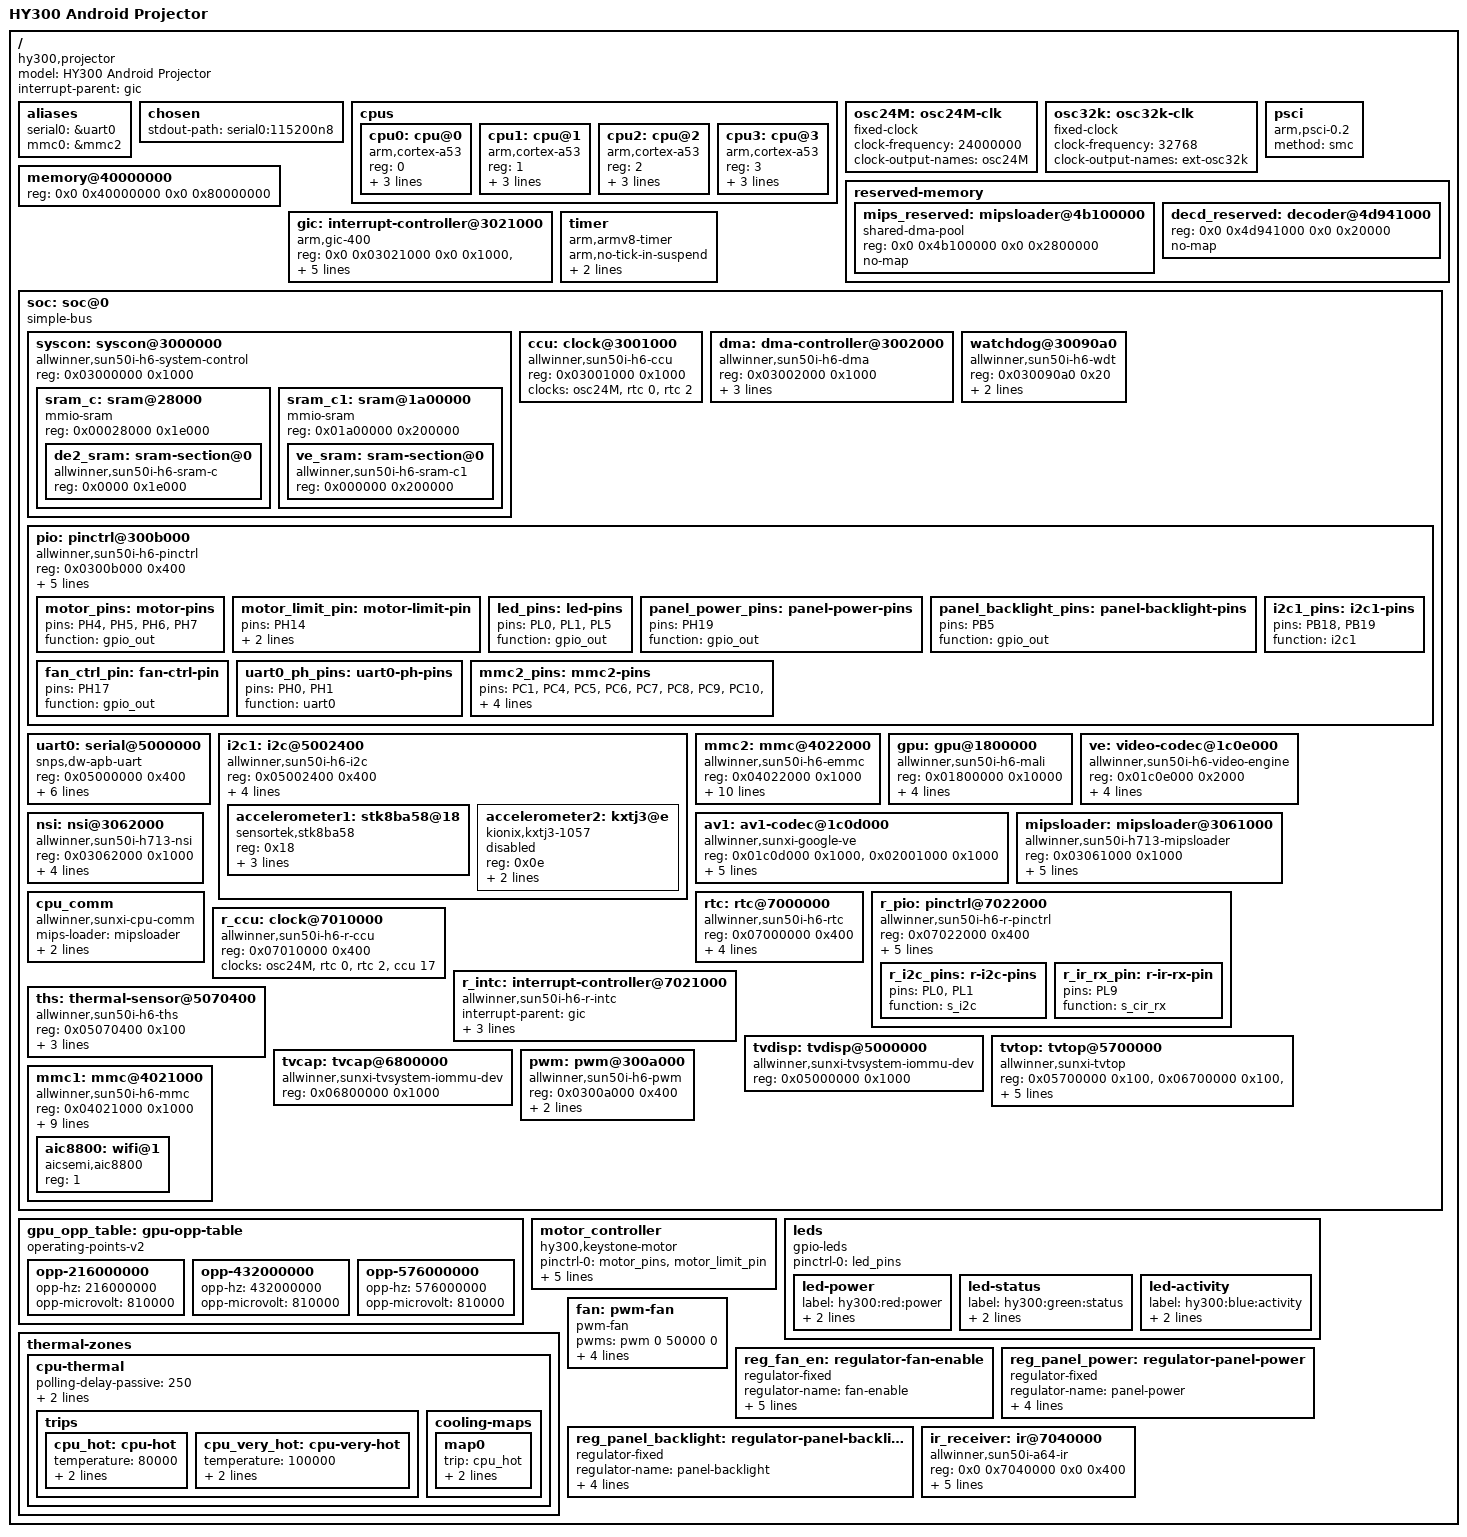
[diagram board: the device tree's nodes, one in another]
// SPDX-License-Identifier: (GPL-2.0+ OR MIT)
/*
 * Device Tree for HY300 Android Projector with Allwinner H713 SoC
 * 
 * Based on hardware analysis from factory DTB files:
 * - Allwinner H713 SoC (sun50iw12p1, tv303 platform)
 * - MIPS co-processor for display subsystem
 * - Mali-Midgard GPU architecture
 * - Projector-specific hardware (motors, sensors, thermal management)
 *
 * Copyright (c) 2025 Linux on HY300 Project
 */

/dts-v1/;

/ {
	model = "HY300 Android Projector";
	compatible = "hy300,projector", "allwinner,sun50i-h713", "allwinner,sun50i-h6";

	#address-cells = <2>;
	#size-cells = <2>;

	interrupt-parent = <&gic>;

	aliases {
		serial0 = &uart0;
		mmc0 = &mmc2;
	};

	chosen {
		stdout-path = "serial0:115200n8";
	};

	/*
	 * ARM Cortex-A53 CPU configuration
	 * H713 SoC: Quad-core ARM64 Cortex-A53
	 */
	cpus {
		#address-cells = <1>;
		#size-cells = <0>;

		cpu0: cpu@0 {
			compatible = "arm,cortex-a53";
			device_type = "cpu";
			reg = <0>;
			enable-method = "psci";
			clocks = <&ccu 0>; /* CLK_CPUX */
			clock-latency-ns = <244144>; /* 8 32k periods */
			#cooling-cells = <2>;
		};

		cpu1: cpu@1 {
			compatible = "arm,cortex-a53";
			device_type = "cpu";
			reg = <1>;
			enable-method = "psci";
			clocks = <&ccu 0>; /* CLK_CPUX */
			clock-latency-ns = <244144>; /* 8 32k periods */
			#cooling-cells = <2>;
		};

		cpu2: cpu@2 {
			compatible = "arm,cortex-a53";
			device_type = "cpu";
			reg = <2>;
			enable-method = "psci";
			clocks = <&ccu 0>; /* CLK_CPUX */
			clock-latency-ns = <244144>; /* 8 32k periods */
			#cooling-cells = <2>;
		};

		cpu3: cpu@3 {
			compatible = "arm,cortex-a53";
			device_type = "cpu";
			reg = <3>;
			enable-method = "psci";
			clocks = <&ccu 0>; /* CLK_CPUX */
			clock-latency-ns = <244144>; /* 8 32k periods */
			#cooling-cells = <2>;
		};
	};

	/*
	 * External oscillators - using H6 reference values
	 * H713 uses same crystal configuration as H6
	 */
	osc24M: osc24M-clk {
		#clock-cells = <0>;
		compatible = "fixed-clock";
		clock-frequency = <24000000>;
		clock-output-names = "osc24M";
	};

	osc32k: osc32k-clk {
		#clock-cells = <0>;
		compatible = "fixed-clock";
		clock-frequency = <32768>;
		clock-output-names = "ext-osc32k";
	};

	/*
	 * Power management and CPU idle
	 */
	psci {
		compatible = "arm,psci-0.2";
		method = "smc";
	};

	/*
	 * Memory configuration
	 * DRAM parameters extracted from boot0.bin:
	 * - DDR3-1600 configuration
	 * - Factory configuration supports up to 4GB
	 */
	memory@40000000 {
		device_type = "memory";
		/* Memory size will be filled by U-Boot */
		reg = <0x0 0x40000000 0x0 0x80000000>; /* 2GB default */
	};

	/*
	 * Reserved memory regions for special hardware
	 * Based on factory DTB analysis: MIPS co-processor and decoders
	 */
	reserved-memory {
		#address-cells = <2>;
		#size-cells = <2>;
		ranges;

		/*
		 * MIPS co-processor firmware and working memory
		 * Exact 40MB allocation based on factory memory layout analysis
		 */
		mips_reserved: mipsloader@4b100000 {
			compatible = "shared-dma-pool";
			reg = <0x0 0x4b100000 0x0 0x2800000>; /* 40MB */
			no-map;
		};

		/*
		 * Video decoder buffer
		 * Factory configuration: 0x4d941000 size 0x20000 (128KB)
		 */
		decd_reserved: decoder@4d941000 {
			reg = <0x0 0x4d941000 0x0 0x20000>;
			no-map;
		};
	};

	/*
	 * ARM Generic Interrupt Controller
	 * H713 uses same GIC configuration as H6
	 */
	gic: interrupt-controller@3021000 {
		compatible = "arm,gic-400";
		reg = <0x0 0x03021000 0x0 0x1000>,
		      <0x0 0x03022000 0x0 0x2000>,
		      <0x0 0x03024000 0x0 0x2000>,
		      <0x0 0x03026000 0x0 0x2000>;
		interrupts = <1 9 0xff04>; /* GIC_PPI 9 (GIC_CPU_MASK_SIMPLE(4) | IRQ_TYPE_LEVEL_HIGH) */
		interrupt-controller;
		#interrupt-cells = <3>;
	};

	/*
	 * Timer configuration
	 * ARM architected timer - H6 compatible
	 */
	timer {
		compatible = "arm,armv8-timer";
		arm,no-tick-in-suspend;
		interrupts = <1 13 0xff08>, /* GIC_PPI 13 (GIC_CPU_MASK_SIMPLE(4) | IRQ_TYPE_LEVEL_LOW) */
			     <1 14 0xff08>, /* GIC_PPI 14 (GIC_CPU_MASK_SIMPLE(4) | IRQ_TYPE_LEVEL_LOW) */
			     <1 11 0xff08>, /* GIC_PPI 11 (GIC_CPU_MASK_SIMPLE(4) | IRQ_TYPE_LEVEL_LOW) */
			     <1 10 0xff08>; /* GIC_PPI 10 (GIC_CPU_MASK_SIMPLE(4) | IRQ_TYPE_LEVEL_LOW) */
	};

	soc: soc@0 {
		compatible = "simple-bus";
		#address-cells = <1>;
		#size-cells = <1>;
		ranges = <0x0 0x0 0x0 0x40000000>;

		/*
		 * System Control Unit
		 * H713 system control - H6 compatible
		 */
		syscon: syscon@3000000 {
			compatible = "allwinner,sun50i-h6-system-control";
			reg = <0x03000000 0x1000>;
			#address-cells = <1>;
			#size-cells = <1>;
			ranges;

			sram_c: sram@28000 {
				compatible = "mmio-sram";
				reg = <0x00028000 0x1e000>;
				#address-cells = <1>;
				#size-cells = <1>;
				ranges = <0 0x00028000 0x1e000>;

				de2_sram: sram-section@0 {
					compatible = "allwinner,sun50i-h6-sram-c",
						     "allwinner,sun50i-a64-sram-c";
					reg = <0x0000 0x1e000>;
				};
			};

			sram_c1: sram@1a00000 {
				compatible = "mmio-sram";
				reg = <0x01a00000 0x200000>;
				#address-cells = <1>;
				#size-cells = <1>;
				ranges = <0 0x01a00000 0x200000>;

				ve_sram: sram-section@0 {
					compatible = "allwinner,sun50i-h6-sram-c1",
						     "allwinner,sun4i-a10-sram-c1";
					reg = <0x000000 0x200000>;
				};
			};
		};

		/*
		 * Clock Control Unit
		 * H713 CCU - H6 compatible with tv303 platform extensions
		 */
		ccu: clock@3001000 {
			compatible = "allwinner,sun50i-h6-ccu";
			reg = <0x03001000 0x1000>;
			clocks = <&osc24M>, <&rtc 0>, <&rtc 2>;
			clock-names = "hosc", "losc", "iosc";
			#clock-cells = <1>;
			#reset-cells = <1>;
		};

		/*
		 * DMA Controller
		 * H6-compatible DMA for peripheral access
		 */
		dma: dma-controller@3002000 {
			compatible = "allwinner,sun50i-h6-dma";
			reg = <0x03002000 0x1000>;
			interrupts = <0 43 4>; /* GIC_SPI 43 IRQ_TYPE_LEVEL_HIGH */
			clocks = <&ccu 1>, <&ccu 2>, <&ccu 125>; /* CLK_BUS_DMA, CLK_MBUS_DMA, CLK_VINCAP_DMA */
			clock-names = "bus", "mbus", "vincap";
			resets = <&ccu 0>; /* RST_BUS_DMA */
			#dma-cells = <1>;
		};

		/*
		 * Watchdog Timer
		 * H6-compatible watchdog
		 */
		watchdog@30090a0 {
			compatible = "allwinner,sun50i-h6-wdt",
				     "allwinner,sun6i-a31-wdt";
			reg = <0x030090a0 0x20>;
			interrupts = <0 50 4>; /* GIC_SPI 50 IRQ_TYPE_LEVEL_HIGH */
			clocks = <&osc24M>;
		};

		/*
		 * Pin Controller
		 * H713 pinctrl with projector-specific GPIO assignments
		 */
		pio: pinctrl@300b000 {
			compatible = "allwinner,sun50i-h6-pinctrl";
			reg = <0x0300b000 0x400>;
			interrupt-parent = <&r_intc>;
			interrupts = <0 51 4>, /* GIC_SPI 51 IRQ_TYPE_LEVEL_HIGH */
				     <0 53 4>, /* GIC_SPI 53 IRQ_TYPE_LEVEL_HIGH */
				     <0 54 4>, /* GIC_SPI 54 IRQ_TYPE_LEVEL_HIGH */
				     <0 59 4>; /* GIC_SPI 59 IRQ_TYPE_LEVEL_HIGH */
			clocks = <&ccu 5>, <&osc24M>, <&rtc 0>; /* CLK_APB1 */
			clock-names = "apb", "hosc", "losc";
			gpio-controller;
			#gpio-cells = <3>;
			interrupt-controller;
			#interrupt-cells = <3>;

			/*
			 * Projector-specific GPIO configurations
			 * Based on factory DTB analysis from HY300_SPECIFIC_HARDWARE.md
			 */

			/* Motor control for electronic keystone correction */
			motor_pins: motor-pins {
				pins = "PH4", "PH5", "PH6", "PH7";
				function = "gpio_out";
			};

			motor_limit_pin: motor-limit-pin {
				pins = "PH14";
				function = "gpio_in";
				bias-pull-up;
			};

			/* Status LEDs */
			led_pins: led-pins {
				pins = "PL0", "PL1", "PL5";
				function = "gpio_out";
			};

			/* Panel power control */
			panel_power_pins: panel-power-pins {
				pins = "PH19";
				function = "gpio_out";
			};

			panel_backlight_pins: panel-backlight-pins {
				pins = "PB5";
				function = "gpio_out";
			};

			/* Fan control */
			fan_ctrl_pin: fan-ctrl-pin {
				pins = "PH17";
				function = "gpio_out";
			};

			/* UART0 for debug console */
			uart0_ph_pins: uart0-ph-pins {
				pins = "PH0", "PH1";
				function = "uart0";
			};

			/* I2C for sensors */
			i2c1_pins: i2c1-pins {
				pins = "PB18", "PB19";
				function = "i2c1";
			};

			/* MMC2 for eMMC */
			mmc2_pins: mmc2-pins {
				pins = "PC1", "PC4", "PC5", "PC6", "PC7",
				       "PC8", "PC9", "PC10", "PC11", "PC12",
				       "PC13", "PC14", "PC15", "PC16";
				function = "mmc2";
				drive-strength = <30>;
				bias-pull-up;
			};
		};

		/*
		 * UART0 - Debug console
		 * Primary debug interface for the system
		 */
		uart0: serial@5000000 {
			compatible = "snps,dw-apb-uart";
			reg = <0x05000000 0x400>;
			interrupts = <0 0 4>; /* GIC_SPI 0 IRQ_TYPE_LEVEL_HIGH */
			reg-shift = <2>;
			reg-io-width = <4>;
			clocks = <&ccu 6>; /* CLK_BUS_UART0 */
			resets = <&ccu 2>; /* RST_BUS_UART0 */
			pinctrl-names = "default";
			pinctrl-0 = <&uart0_ph_pins>;
			status = "okay";
		};

		/*
		 * I2C1 - Sensors
		 * Connected to accelerometers for auto-keystone correction
		 */
		i2c1: i2c@5002400 {
			compatible = "allwinner,sun50i-h6-i2c",
				     "allwinner,sun6i-a31-i2c";
			reg = <0x05002400 0x400>;
			interrupts = <0 7 4>; /* GIC_SPI 7 IRQ_TYPE_LEVEL_HIGH */
			clocks = <&ccu 7>; /* CLK_BUS_I2C1 */
			resets = <&ccu 3>; /* RST_BUS_I2C1 */
			pinctrl-names = "default";
			pinctrl-0 = <&i2c1_pins>;
			status = "okay";
			#address-cells = <1>;
			#size-cells = <0>;

			/*
			 * Accelerometer sensors for keystone correction
			 * Factory DTB shows two different accelerometer models with interrupt GPIOs
			 */
			accelerometer1: stk8ba58@18 {
				compatible = "sensortek,stk8ba58";
				reg = <0x18>;
				interrupt-parent = <&pio>;
				interrupts = <1 0 2>; /* PB0, IRQ_TYPE_EDGE_FALLING */
				stk,direction = <2>;
			};

			/* Alternative accelerometer - different I2C address from factory analysis */
			accelerometer2: kxtj3@e {
				compatible = "kionix,kxtj3-1057";
				reg = <0x0e>; /* Factory DTB uses 0x0e, not 0x18 */
				interrupt-parent = <&pio>;
				interrupts = <1 0 2>; /* PB0, IRQ_TYPE_EDGE_FALLING */
				status = "disabled"; /* Enable based on hardware detection */
			};

			/* Alternative accelerometer - may be different hardware revisions */
		};

		/*
		 * MMC2 - eMMC Storage
		 * Primary storage device
		 */
		mmc2: mmc@4022000 {
			compatible = "allwinner,sun50i-h6-emmc",
				     "allwinner,sun50i-a64-emmc";
			reg = <0x04022000 0x1000>;
			interrupts = <0 37 4>; /* GIC_SPI 37 IRQ_TYPE_LEVEL_HIGH */
			clocks = <&ccu 3>, <&ccu 4>; /* CLK_BUS_MMC2, CLK_MMC2 */
			clock-names = "ahb", "mmc";
			resets = <&ccu 1>; /* RST_BUS_MMC2 */
			reset-names = "ahb";
			pinctrl-names = "default";
			pinctrl-0 = <&mmc2_pins>;
			max-frequency = <150000000>;
			cap-mmc-highspeed;
			mmc-ddr-1_8v;
			mmc-hs200-1_8v;
			non-removable;
			bus-width = <8>;
			status = "okay";
		};

		/*
		 * GPU - Mali-Midgard
		 * Factory DTB shows mali-midgard compatible GPU
		 * Memory base: 0x01800000, register space: 64KB
		 */
		gpu: gpu@1800000 {
			compatible = "allwinner,sun50i-h6-mali",
				     "arm,mali-midgard";
			reg = <0x01800000 0x10000>;
			interrupts = <0 117 4>, /* GIC_SPI 117 IRQ_TYPE_LEVEL_HIGH */
				     <0 118 4>, /* GIC_SPI 118 IRQ_TYPE_LEVEL_HIGH */
				     <0 76 4>;  /* GIC_SPI 76 IRQ_TYPE_LEVEL_HIGH */
			interrupt-names = "job", "mmu", "gpu";
			clocks = <&ccu 8>, <&ccu 9>; /* CLK_GPU, CLK_BUS_GPU */
			clock-names = "core", "bus";
			resets = <&ccu 4>; /* RST_BUS_GPU */
			status = "okay";

			operating-points-v2 = <&gpu_opp_table>;
		};

		/*
		 * Video Engine - CedarX VPU
		 * Hardware video decoding for H.264, H.265, VP8, VP9
		 * Based on H6 video engine with H713 enhancements
		 */
		ve: video-codec@1c0e000 {
			compatible = "allwinner,sun50i-h6-video-engine";
			reg = <0x01c0e000 0x2000>;
			clocks = <&ccu 33>, <&ccu 32>, <&ccu 53>; /* CLK_BUS_VE, CLK_VE, CLK_MBUS_VE */
			clock-names = "ahb", "mod", "ram";
			resets = <&ccu 7>; /* RST_BUS_VE */
			interrupts = <0 89 4>; /* GIC_SPI 89 IRQ_TYPE_LEVEL_HIGH */
			allwinner,sram = <&ve_sram 1>;
			status = "okay";
		};

		/*
		 * AV1 Video Engine - Google Collaboration Hardware
		 * CRITICAL DISCOVERY: H713 has dedicated AV1 hardware acceleration
		 * Compatible string "sunxi-google-ve" indicates Google partnership
		 * Provides hardware AV1 decode - major performance advantage
		 */
		av1: av1-codec@1c0d000 {
			compatible = "allwinner,sunxi-google-ve";
			reg = <0x01c0d000 0x1000>, <0x02001000 0x1000>;
			interrupts = <0 107 4>; /* GIC_SPI 107 IRQ_TYPE_LEVEL_HIGH */
			clocks = <&ccu 33>, <&ccu 34>, <&ccu 32>, <&ccu 53>; /* bus_ve, bus_av1, av1, mbus_av1 */
			clock-names = "bus_ve", "bus_av1", "av1", "mbus_av1";
			resets = <&ccu 7>, <&ccu 8>; /* reset_ve, reset_av1 */
			reset-names = "reset_ve", "reset_av1";
			iommus = <&iommu 5 1>;
			power-domains = <&power_domains 4>;
			status = "okay";
		};

		/*
		 * MIPS Co-processor Loader
		 * Critical component for display subsystem
		 * Factory configuration: register base 0x3061000
		 * Memory layout: 40MB region for firmware, config, and frame buffers
		 */
		mipsloader: mipsloader@3061000 {
			compatible = "allwinner,sun50i-h713-mipsloader",
				     "allwinner,sunxi-mipsloader";
			reg = <0x03061000 0x1000>;
			memory-region = <&mips_reserved>;
			interrupts = <0 90 4>; /* GIC_SPI 90 IRQ_TYPE_LEVEL_HIGH */
			clocks = <&ccu 10>; /* CLK_MBUS */
			clock-names = "mips";
			resets = <&ccu 5>; /* RST_MBUS */
			reset-names = "mips";
			status = "okay";

			/*
			 * MIPS firmware loading interface
			 * Requires display.bin firmware file (1.25MB)
			 * Factory CRC32: 0xe0376895
			 */
			firmware-name = "display.bin";
		};

		/*
		 * Network Service Interface (NSI)
		 * ARM-MIPS communication interface with IRQ 110
		 */
		nsi: nsi@3062000 {
			compatible = "allwinner,sun50i-h713-nsi", "allwinner,sunxi-nsi";
			reg = <0x03062000 0x1000>;
			interrupts = <0 110 4>; /* GIC_SPI 110 IRQ_TYPE_LEVEL_HIGH */
			memory-region = <&mips_reserved>;
			clocks = <&ccu 10>, <&ccu 10>; /* CLK_MBUS */
			clock-names = "bus", "mips";
			resets = <&ccu 5>; /* RST_MBUS */
			status = "okay";
		};

		/*
		 * CPU Communication Interface
		 * High-level ARM-MIPS communication for HDMI control
		 */
		cpu_comm: cpu_comm {
			compatible = "allwinner,sunxi-cpu-comm";
			mips-loader = <&mipsloader>;
			nsi-interface = <&nsi>;
			shared-memory = <&mips_reserved>;
			status = "okay";
		};

		/*
		 * RTC and Power Management IC
		 * H6-compatible RTC
		 */
		rtc: rtc@7000000 {
			compatible = "allwinner,sun50i-h6-rtc";
			reg = <0x07000000 0x400>;
			interrupt-parent = <&r_intc>;
			interrupts = <0 101 4>, /* GIC_SPI 101 IRQ_TYPE_LEVEL_HIGH */
				     <0 102 4>; /* GIC_SPI 102 IRQ_TYPE_LEVEL_HIGH */
			clock-output-names = "osc32k", "osc32k-out", "iosc";
			clocks = <&osc32k>;
			#clock-cells = <1>;
		};

		/*
		 * R_PIO - Power management domain GPIO
		 * Controls critical power functions
		 */
		r_pio: pinctrl@7022000 {
			compatible = "allwinner,sun50i-h6-r-pinctrl";
			reg = <0x07022000 0x400>;
			interrupt-parent = <&r_intc>;
			interrupts = <0 105 4>, /* GIC_SPI 105 IRQ_TYPE_LEVEL_HIGH */
				     <0 111 4>; /* GIC_SPI 111 IRQ_TYPE_LEVEL_HIGH */
			clocks = <&r_ccu 16>, <&osc24M>, <&rtc 0>; /* CLK_R_APB1 */
			clock-names = "apb", "hosc", "losc";
			gpio-controller;
			#gpio-cells = <3>;
			interrupt-controller;
			#interrupt-cells = <3>;

			r_i2c_pins: r-i2c-pins {
				pins = "PL0", "PL1";
				function = "s_i2c";
			};
		};

		/*
		 * R_CCU - Power management domain clocks
		 */
		r_ccu: clock@7010000 {
			compatible = "allwinner,sun50i-h6-r-ccu";
			reg = <0x07010000 0x400>;
			clocks = <&osc24M>, <&rtc 0>, <&rtc 2>, <&ccu 17>; /* CLK_PLL_PERIPH0 */
			clock-names = "hosc", "losc", "iosc", "pll-periph";
			#clock-cells = <1>;
			#reset-cells = <1>;
		};

		/*
		 * R_INTC - Power management domain interrupt controller
		 */
		r_intc: interrupt-controller@7021000 {
			compatible = "allwinner,sun50i-h6-r-intc";
			interrupt-parent = <&gic>;
			reg = <0x07021000 0x400>;
			interrupts = <0 96 4>; /* GIC_SPI 96 IRQ_TYPE_LEVEL_HIGH */
			interrupt-controller;
			#interrupt-cells = <2>;
		};

		/*
		 * Thermal sensor
		 */
		ths: thermal-sensor@5070400 {
			compatible = "allwinner,sun50i-h6-ths";
			reg = <0x05070400 0x100>;
			interrupts = <0 15 4>; /* GIC_SPI 15 IRQ_TYPE_LEVEL_HIGH */
			clocks = <&ccu 12>; /* CLK_BUS_THS */
			clock-names = "bus";
			resets = <&ccu 6>; /* RST_BUS_THS */
			#thermal-sensor-cells = <1>;
		};

		/*
		 * TV Display System (tvdisp@5000000)
		 * HDMI input display processing
		 */
		tvdisp: tvdisp@5000000 {
			compatible = "allwinner,sunxi-tvsystem-iommu-dev";
			reg = <0x05000000 0x1000>;
			/* iommus = <&iommu 3 1>; */ /* Stream 0x03, Context 0x01 - TODO: Add IOMMU */
			status = "okay";
		};

		/*
		 * TV System Control Hub (tvtop@5700000)  
		 * Primary TV capture and display control
		 */
		tvtop: tvtop@5700000 {
			compatible = "allwinner,sunxi-tvtop";
			reg = <0x05700000 0x100>,   /* TV TOP control registers */
			      <0x06700000 0x100>,   /* TV secondary control */
			      <0x06e00000 0x100>;   /* TV extended control */
			
			interrupts = <0 110 4>; /* GIC_SPI 110 IRQ_TYPE_LEVEL_HIGH */
			
			/* Clock configuration - TV capture specific clocks */
			clocks = <&ccu 134>,  /* CLK_BUS_DISP */
				 <&ccu 130>,  /* CLK_BUS_TVCAP */ 
				 <&ccu 123>,  /* CLK_BUS_DEMOD */
				 <&ccu 124>,  /* CLK_CAP_300M */
				 <&ccu 125>,  /* CLK_VINCAP_DMA */
				 <&ccu 127>,  /* CLK_HDMI_AUDIO_BUS */
				 <&ccu 128>;  /* CLK_HDMI_AUDIO */
			clock-names = "clk_bus_disp", "clk_bus_tvcap", "clk_bus_demod",
				      "cap_300m", "vincap_dma_clk", 
				      "hdmi_audio_bus", "hdmi_audio_clk";
			
			/* Reset lines */
			resets = <&ccu 57>,   /* RST_BUS_DISP */
				 <&ccu 56>,   /* RST_BUS_TVCAP */
				 <&ccu 55>;   /* RST_BUS_DEMOD */
			reset-names = "reset_bus_disp", "reset_bus_tvcap", "reset_bus_demod";
			
			/* Power domain integration - TODO: Add power domains */
			/* power-domains = <&power_domains 2>, <&power_domains 1>; */
			/* power-domain-names = "pd_tvcap", "pd_tvfe"; */
			
			status = "okay";
		};

		/*
		 * TV Capture Interface (tvcap@6800000)
		 * HDMI input capture controller - CRITICAL FOR HDMI INPUT
		 */
		tvcap: tvcap@6800000 {
			compatible = "allwinner,sunxi-tvsystem-iommu-dev";
			reg = <0x06800000 0x1000>;
			/* iommus = <&iommu 4 1>; */ /* Stream 0x04, Context 0x01 - TODO: Add IOMMU */
			status = "okay";
		};

		/* PWM controller for fan speed */
		pwm: pwm@300a000 {
			compatible = "allwinner,sun50i-h6-pwm";
			reg = <0x0300a000 0x400>;
			clocks = <&osc24M>, <&ccu 13>; /* CLK_BUS_PWM */
			clock-names = "mod", "bus";
			resets = <&ccu 7>; /* RST_BUS_PWM */
			#pwm-cells = <3>;
			status = "okay";
		};

		/*
		 * MMC1 - WiFi Module
		 * For AW869A/AIC8800 WiFi module
		 */
		mmc1: mmc@4021000 {
			compatible = "allwinner,sun50i-h6-mmc";
			reg = <0x04021000 0x1000>;
			interrupts = <0 36 4>; /* GIC_SPI 36 IRQ_TYPE_LEVEL_HIGH */
			clocks = <&ccu 14>, <&ccu 15>; /* CLK_BUS_MMC1, CLK_MMC1 */
			clock-names = "ahb", "mmc";
			resets = <&ccu 8>; /* RST_BUS_MMC1 */
			reset-names = "ahb";
			max-frequency = <150000000>;
			cap-sd-highspeed;
			sd-uhs-sdr50;
			sd-uhs-sdr104;
			non-removable;
			bus-width = <4>;
			status = "okay";

			/*
			 * WiFi chip configuration
			 * AW869A/AIC8800 - requires proprietary driver
			 */
			aic8800: wifi@1 {
				compatible = "aicsemi,aic8800";
				reg = <1>;
				/* Additional WiFi configuration will be added in Phase V */
			};
		};
	};

	/*
	 * GPU Operating Points
	 * Performance scaling for Mali-Midgard GPU
	 */
	gpu_opp_table: gpu-opp-table {
		compatible = "operating-points-v2";

		opp-216000000 {
			opp-hz = /bits/ 64 <216000000>;
			opp-microvolt = <810000>;
		};

		opp-432000000 {
			opp-hz = /bits/ 64 <432000000>;
			opp-microvolt = <810000>;
		};

		opp-576000000 {
			opp-hz = /bits/ 64 <576000000>;
			opp-microvolt = <810000>;
		};
	};

	/*
	 * HY300 Projector-Specific Hardware
	 * Based on factory DTB analysis and HY300_SPECIFIC_HARDWARE.md
	 */

	/* Motor control for electronic keystone correction */
	motor_controller {
		compatible = "hy300,keystone-motor";
		pinctrl-names = "default";
		pinctrl-0 = <&motor_pins>, <&motor_limit_pin>;

		/* Stepper motor control GPIOs */
		phase-gpios = <&pio 7 4 0>,  /* PH4, GPIO_ACTIVE_HIGH */
			      <&pio 7 5 0>,  /* PH5, GPIO_ACTIVE_HIGH */
			      <&pio 7 6 0>,  /* PH6, GPIO_ACTIVE_HIGH */
			      <&pio 7 7 0>;  /* PH7, GPIO_ACTIVE_HIGH */

		/* Limit switch for end-of-travel detection */
		limit-gpio = <&pio 7 14 1>;    /* PH14, GPIO_ACTIVE_LOW */

		/* Timing parameters from factory configuration */
		phase-delay-us = <1000>;  /* Delay between phase changes */
		step-delay-ms = <2>;      /* Delay between steps */

		status = "okay";
	};

	/* Status LEDs */
	leds {
		compatible = "gpio-leds";
		pinctrl-names = "default";
		pinctrl-0 = <&led_pins>;

		led-power {
			label = "hy300:red:power";
			gpios = <&pio 11 0 0>;  /* PL0, GPIO_ACTIVE_HIGH */
			default-state = "on";
		};

		led-status {
			label = "hy300:green:status";
			gpios = <&pio 11 1 0>;  /* PL1, GPIO_ACTIVE_HIGH */
			default-state = "off";
		};

		led-activity {
			label = "hy300:blue:activity";
			gpios = <&pio 11 5 0>;  /* PL5, GPIO_ACTIVE_HIGH */
			linux,default-trigger = "heartbeat";
		};
	};

	/* Thermal management - cooling fan */
	thermal-zones {
		cpu-thermal {
			polling-delay-passive = <250>;
			polling-delay = <1000>;
			thermal-sensors = <&ths 0>;

			trips {
				cpu_hot: cpu-hot {
					temperature = <80000>;
					hysteresis = <2000>;
					type = "active";
				};

				cpu_very_hot: cpu-very-hot {
					temperature = <100000>;
					hysteresis = <0>;
					type = "critical";
				};
			};

			cooling-maps {
				map0 {
					trip = <&cpu_hot>;
					cooling-device = <&cpu0 0 0>, /* THERMAL_NO_LIMIT THERMAL_NO_LIMIT */
							 <&cpu1 0 0>, /* THERMAL_NO_LIMIT THERMAL_NO_LIMIT */
							 <&cpu2 0 0>, /* THERMAL_NO_LIMIT THERMAL_NO_LIMIT */
							 <&cpu3 0 0>, /* THERMAL_NO_LIMIT THERMAL_NO_LIMIT */
							 <&fan 0 0>;  /* THERMAL_NO_LIMIT THERMAL_NO_LIMIT */
				};
			};
		};
	};

	/* Cooling fan - PWM controlled */
	fan: pwm-fan {
		compatible = "pwm-fan";
		pwms = <&pwm 0 50000 0>;  /* 20kHz PWM */
		cooling-min-state = <0>;
		cooling-max-state = <255>;
		#cooling-cells = <2>;
		pinctrl-names = "default";
		pinctrl-0 = <&fan_ctrl_pin>;

		/* Secondary GPIO control for fan enable */
		fan-supply = <&reg_fan_en>;
	};

	/* Voltage regulators */
	reg_fan_en: regulator-fan-enable {
		compatible = "regulator-fixed";
		regulator-name = "fan-enable";
		regulator-min-microvolt = <3300000>;
		regulator-max-microvolt = <3300000>;
		gpio = <&pio 7 17 0>;  /* PH17, GPIO_ACTIVE_HIGH */
		enable-active-high;
		regulator-always-on;
	};

	/* Panel power control */
	reg_panel_power: regulator-panel-power {
		compatible = "regulator-fixed";
		regulator-name = "panel-power";
		regulator-min-microvolt = <3300000>;
		regulator-max-microvolt = <3300000>;
		gpio = <&pio 7 19 0>;  /* PH19, GPIO_ACTIVE_HIGH */
		enable-active-high;
	};

	/* Panel backlight (LED light source) control */
	reg_panel_backlight: regulator-panel-backlight {
		compatible = "regulator-fixed";
		regulator-name = "panel-backlight";
		regulator-min-microvolt = <3300000>;
		regulator-max-microvolt = <3300000>;
		gpio = <&pio 1 5 0>;   /* PB5, GPIO_ACTIVE_HIGH */
		enable-active-high;
	};

	/*
	 * IR Receiver for Remote Control
	 * Based on factory DTB analysis: s_cir@7040000 on GPIO PL9
	 * Enables remote control input for Kodi navigation
	 */
	ir_receiver: ir@7040000 {
		compatible = "allwinner,sun50i-a64-ir", "allwinner,sun6i-a31-ir";
		reg = <0x0 0x7040000 0x0 0x400>;
		clocks = <&r_ccu 0x04>, <&r_ccu 0x0b>;
		clock-names = "apb", "ir";
		resets = <&r_ccu 0x00>;
		interrupts = <0x00 0x25 0x04>;
		pinctrl-names = "default";
		pinctrl-0 = <&r_ir_rx_pin>;
		status = "okay";
		linux,rc-map-name = "rc-hy300";
	};
};

/* IR receiver pin configuration - PL9 for IR input */
&r_pio {
	r_ir_rx_pin: r-ir-rx-pin {
		pins = "PL9";
		function = "s_cir_rx";
	};
};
